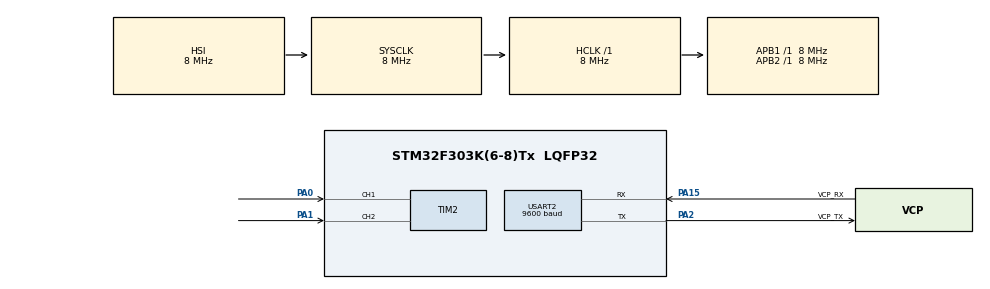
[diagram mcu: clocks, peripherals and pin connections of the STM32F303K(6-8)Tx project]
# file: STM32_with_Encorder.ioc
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Mcu.Family=STM32F3
Mcu.Name=STM32F303K(6-8)Tx
Mcu.Package=LQFP32
NVIC.PriorityGroup=NVIC_PRIORITYGROUP_4
PA0.Signal=S_TIM2_CH1_ETR
PA1.Signal=S_TIM2_CH2
PA13.GPIO_Label=SWDIO
PA13.Mode=Serial_Wire
PA13.Signal=SYS_JTMS-SWDIO
PA14.GPIO_Label=SWCLK
PA14.Mode=Serial_Wire
PA14.Signal=SYS_JTCK-SWCLK
PA15.GPIO_Label=VCP_RX
PA15.Mode=Asynchronous
PA15.Signal=USART2_RX
PA2.GPIO_Label=VCP_TX
PA2.Mode=Asynchronous
PA2.Signal=USART2_TX
PF0\ /\ OSC_IN.GPIO_Label=MCO
PF0\ /\ OSC_IN.Mode=HSE-External-Clock-Source
PF0\ /\ OSC_IN.Signal=RCC_OSC_IN
ProjectManager.HeapSize=0x200
ProjectManager.StackSize=0x400
ProjectManager.TargetToolchain=STM32CubeIDE
RCC.AHBFreq_Value=8000000
RCC.APB1Freq_Value=8000000
RCC.APB2Freq_Value=8000000
RCC.CortexFreq_Value=8000000
RCC.HSE_VALUE=8000000
RCC.HSI_VALUE=8000000
RCC.SYSCLKFreq_VALUE=8000000
SH.S_TIM2_CH1_ETR.0=TIM2_CH1,Encoder_Interface
SH.S_TIM2_CH2.0=TIM2_CH2,Encoder_Interface
USART2.BaudRate=9600
USART2.VirtualMode-Asynchronous=VM_ASYNC
board=NUCLEO-F303K8

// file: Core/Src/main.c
	/* USER CODE BEGIN Header */
/**
  ******************************************************************************
  * @file           : main.c
  * @brief          : Main program body
  ******************************************************************************
  * @attention
  *
  * Copyright (c) 2025 STMicroelectronics.
  * All rights reserved.
  *
  * This software is licensed under terms that can be found in the LICENSE file
  * in the root directory of this software component.
  * If no LICENSE file comes with this software, it is provided AS-IS.
  *
  ******************************************************************************
  */
/* USER CODE END Header */
#include "main.h"

/* USER CODE BEGIN Includes */
#include <stdio.h>
/* USER CODE END Includes */

TIM_HandleTypeDef htim2;

UART_HandleTypeDef huart2;

void SystemClock_Config(void);
static void MX_GPIO_Init(void);
static void MX_TIM2_Init(void);
static void MX_USART2_UART_Init(void);

int main(void)
{

  /* USER CODE BEGIN 1 */
  setbuf(stdout, NULL);
  /* USER CODE END 1 */

  /* MCU Configuration--------------------------------------------------------*/

  /* Reset of all peripherals, Initializes the Flash interface and the Systick. */
  HAL_Init();

  /* Configure the system clock */
  SystemClock_Config();

  /* Initialize all configured peripherals */
  MX_GPIO_Init();
  MX_TIM2_Init();
  MX_USART2_UART_Init();
  /* USER CODE BEGIN 2 */
  const int CP = 4294967295; // カウンターピリオド
  int count;
  __HAL_TIM_SET_COUNTER(&htim2, CP/2);
  HAL_TIM_Encoder_Start(&htim2, TIM_CHANNEL_1);
  HAL_TIM_Encoder_Start(&htim2, TIM_CHANNEL_2);
  /* USER CODE END 2 */

  /* Infinite loop */
  /* USER CODE BEGIN WHILE */
  while (1)
  {
	// TIMのCNTから値を取り出してprint
	count = TIM2->CNT;
	printf("%d\r\n",count - CP / 2);
	HAL_Delay(50);
    /* USER CODE END WHILE */

  }
}

void SystemClock_Config(void)
{
  RCC_OscInitTypeDef RCC_OscInitStruct = {0};
  RCC_ClkInitTypeDef RCC_ClkInitStruct = {0};

  /** Initializes the RCC Oscillators according to the specified parameters
  * in the RCC_OscInitTypeDef structure.
  */
  RCC_OscInitStruct.OscillatorType = RCC_OSCILLATORTYPE_HSI;
  RCC_OscInitStruct.HSIState = RCC_HSI_ON;
  RCC_OscInitStruct.HSICalibrationValue = RCC_HSICALIBRATION_DEFAULT;
  RCC_OscInitStruct.PLL.PLLState = RCC_PLL_NONE;
  if (HAL_RCC_OscConfig(&RCC_OscInitStruct) != HAL_OK)
  {
    Error_Handler();
  }

  /** Initializes the CPU, AHB and APB buses clocks
  */
  RCC_ClkInitStruct.ClockType = RCC_CLOCKTYPE_HCLK|RCC_CLOCKTYPE_SYSCLK
                              |RCC_CLOCKTYPE_PCLK1|RCC_CLOCKTYPE_PCLK2;
  RCC_ClkInitStruct.SYSCLKSource = RCC_SYSCLKSOURCE_HSI;
  RCC_ClkInitStruct.AHBCLKDivider = RCC_SYSCLK_DIV1;
  RCC_ClkInitStruct.APB1CLKDivider = RCC_HCLK_DIV1;
  RCC_ClkInitStruct.APB2CLKDivider = RCC_HCLK_DIV1;

  if (HAL_RCC_ClockConfig(&RCC_ClkInitStruct, FLASH_LATENCY_0) != HAL_OK)
  {
    Error_Handler();
  }
}

static void MX_TIM2_Init(void)
{

  TIM_Encoder_InitTypeDef sConfig = {0};
  TIM_MasterConfigTypeDef sMasterConfig = {0};

  htim2.Instance = TIM2;
  htim2.Init.Prescaler = 0;
  htim2.Init.CounterMode = TIM_COUNTERMODE_UP;
  htim2.Init.Period = 4294967295;
  htim2.Init.ClockDivision = TIM_CLOCKDIVISION_DIV1;
  htim2.Init.AutoReloadPreload = TIM_AUTORELOAD_PRELOAD_DISABLE;
  sConfig.EncoderMode = TIM_ENCODERMODE_TI1;
  sConfig.IC1Polarity = TIM_ICPOLARITY_RISING;
  sConfig.IC1Selection = TIM_ICSELECTION_DIRECTTI;
  sConfig.IC1Prescaler = TIM_ICPSC_DIV1;
  sConfig.IC1Filter = 0;
  sConfig.IC2Polarity = TIM_ICPOLARITY_RISING;
  sConfig.IC2Selection = TIM_ICSELECTION_DIRECTTI;
  sConfig.IC2Prescaler = TIM_ICPSC_DIV1;
  sConfig.IC2Filter = 0;
  if (HAL_TIM_Encoder_Init(&htim2, &sConfig) != HAL_OK)
  {
    Error_Handler();
  }
  sMasterConfig.MasterOutputTrigger = TIM_TRGO_RESET;
  sMasterConfig.MasterSlaveMode = TIM_MASTERSLAVEMODE_DISABLE;
  if (HAL_TIMEx_MasterConfigSynchronization(&htim2, &sMasterConfig) != HAL_OK)
  {
    Error_Handler();
  }

}

static void MX_USART2_UART_Init(void)
{

  huart2.Instance = USART2;
  huart2.Init.BaudRate = 9600;
  huart2.Init.WordLength = UART_WORDLENGTH_8B;
  huart2.Init.StopBits = UART_STOPBITS_1;
  huart2.Init.Parity = UART_PARITY_NONE;
  huart2.Init.Mode = UART_MODE_TX_RX;
  huart2.Init.HwFlowCtl = UART_HWCONTROL_NONE;
  huart2.Init.OverSampling = UART_OVERSAMPLING_16;
  huart2.Init.OneBitSampling = UART_ONE_BIT_SAMPLE_DISABLE;
  huart2.AdvancedInit.AdvFeatureInit = UART_ADVFEATURE_NO_INIT;
  if (HAL_UART_Init(&huart2) != HAL_OK)
  {
    Error_Handler();
  }

}

static void MX_GPIO_Init(void)
{

  /* GPIO Ports Clock Enable */
  __HAL_RCC_GPIOF_CLK_ENABLE();
  __HAL_RCC_GPIOA_CLK_ENABLE();

}

/* USER CODE BEGIN 4 */
int _write(int file, char *ptr, int len)
{
  HAL_UART_Transmit(&huart2,(uint8_t *)ptr,len,10);
  return len;
}
/* USER CODE END 4 */

void Error_Handler(void)
{
  __disable_irq();
  while (1)
  {
  }
}
